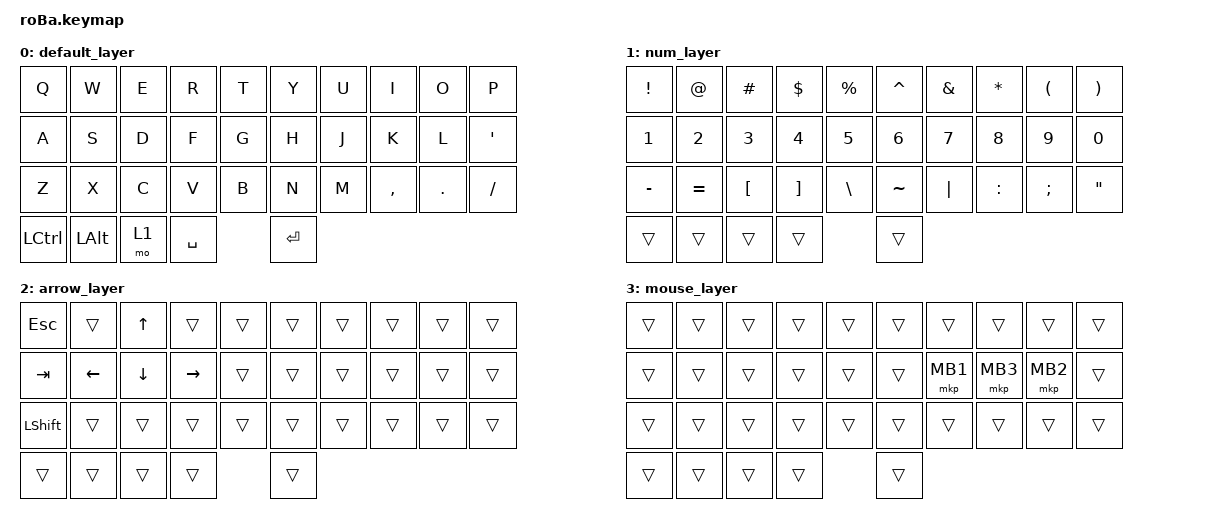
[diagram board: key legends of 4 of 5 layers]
#include <behaviors.dtsi>
#include <dt-bindings/zmk/keys.h>
#include <dt-bindings/zmk/mouse.h>
#include <dt-bindings/zmk/pointing.h>
#include <dt-bindings/zmk/bt.h>

/ {
    behaviors {
        // エンコーダ：スクロール
        encoder_scroll: encoder_scroll {
            compatible = "zmk,behavior-sensor-rotate";
            label = "ENCODER_SCROLL";
            #sensor-binding-cells = <0>;
            bindings = <&msc SCRL_DOWN>, <&msc SCRL_UP>;
        };
    };

    keymap {
        compatible = "zmk,keymap";

        // =========================
        // 0: デフォルト
        // =========================
        default_layer {
            bindings = <
&kp Q   &kp W   &kp E   &kp R   &kp T        &kp Y   &kp U   &kp I   &kp O   &kp P
&kp A   &kp S   &kp D   &kp F   &kp G        &kp H   &kp J   &kp K   &kp L   &kp SQT
&kp Z   &kp X   &kp C   &kp V   &kp B        &kp N   &kp M   &kp COMMA &kp DOT &kp SLASH
&kp LCTRL &kp LALT &mo 1 &kp SPACE          &kp ENTER
>;

            // エンコーダ → スクロール
            sensor-bindings = <&encoder_scroll>;
        };

        // =========================
        // 1: NUM / 記号
        // =========================
        num_layer {
            bindings = <
&kp EXCL &kp AT   &kp HASH &kp DLLR &kp PRCNT     &kp CARET &kp AMPS &kp ASTERISK &kp LPAR &kp RPAR
&kp 1    &kp 2    &kp 3    &kp 4    &kp 5         &kp 6     &kp 7    &kp 8        &kp 9    &kp 0
&kp MINUS &kp EQUAL &kp LBKT &kp RBKT &kp BSLH   &kp TILDE &kp PIPE &kp COLON    &kp SEMI &kp DQT
&trans &trans &trans &trans &trans
>;
        };

        // =========================
        // 2: カーソル操作
        // =========================
        arrow_layer {
            bindings = <
&kp ESC  &trans &kp UP    &trans &trans      &trans &trans &trans &trans &trans
&kp TAB  &kp LEFT &kp DOWN &kp RIGHT &trans  &trans &trans &trans &trans &trans
&kp LSHFT &trans &trans &trans &trans        &trans &trans &trans &trans &trans
&trans &trans &trans &trans &trans
>;
        };

        // =========================
        // 3: マウス
        // =========================
        mouse_layer {
            bindings = <
&trans &trans &trans &trans &trans        &trans &trans &trans &trans &trans
&trans &trans &trans &trans &trans        &trans &mkp MB1 &mkp MB3 &mkp MB2 &trans
&trans &trans &trans &trans &trans        &trans &trans &trans &trans &trans
&trans &trans &trans &trans &trans
>;
        };

        // =========================
        // 4: Bluetooth / システム
        // =========================
        system_layer {
            bindings = <
&bt BT_SEL 0 &bt BT_SEL 1 &bt BT_SEL 2 &bt BT_SEL 3 &bt BT_SEL 4   &trans &trans &trans &trans &trans
&trans &trans &trans &trans &trans                                 &trans &trans &trans &trans &trans
&trans &trans &trans &trans &bootloader                            &trans &trans &trans &trans &bt BT_CLR
&trans &trans &trans &trans &trans                                 &trans &trans &trans &trans &bt BT_CLR_ALL
>;
        };
    };
};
